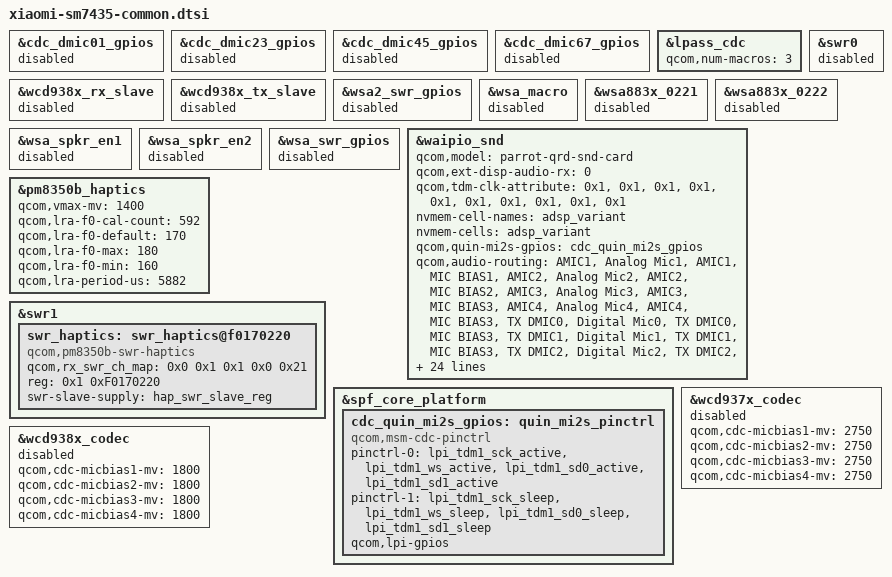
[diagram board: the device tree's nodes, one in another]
#include "parrot-audio-overlay.dtsi"

&cdc_dmic01_gpios {
	status = "disabled";
};

&cdc_dmic23_gpios {
	status = "disabled";
};

&cdc_dmic45_gpios {
	status = "disabled";
};

&cdc_dmic67_gpios {
	status = "disabled";
};

&lpass_cdc {
	qcom,num-macros = <3>;
};

&wcd938x_rx_slave {
	status = "disabled";
};

&wcd938x_tx_slave {
	status = "disabled";
};

&wsa2_swr_gpios {
	status = "disabled";
};

&wsa_macro {
	status = "disabled";
};

&swr0 {
	status = "disabled";
};

&wsa883x_0221 {
	status = "disabled";
};

&wsa883x_0222 {
	status = "disabled";
};

&wsa_spkr_en1 {
	status = "disabled";
};

&wsa_spkr_en2 {
	status = "disabled";
};

&wsa_swr_gpios {
	status = "disabled";
};

&waipio_snd {
    qcom,model = "parrot-qrd-snd-card";
	qcom,ext-disp-audio-rx = <0>;
	qcom,tdm-clk-attribute = <0x1>, <0x1>, <0x1>, <0x1>, <0x1>, <0x1>, <0x1>, <0x1>, <0x1>, <0x1>;
	nvmem-cell-names = "adsp_variant";
	nvmem-cells = <&adsp_variant>;
	qcom,quin-mi2s-gpios = <&cdc_quin_mi2s_gpios>;
	qcom,audio-routing =
		"AMIC1", "Analog Mic1",
		"AMIC1", "MIC BIAS1",
		"AMIC2", "Analog Mic2",
		"AMIC2", "MIC BIAS2",
		"AMIC3", "Analog Mic3",
		"AMIC3", "MIC BIAS3",
		"AMIC4", "Analog Mic4",
		"AMIC4", "MIC BIAS3",
		"TX DMIC0", "Digital Mic0",
		"TX DMIC0", "MIC BIAS3",
		"TX DMIC1", "Digital Mic1",
		"TX DMIC1", "MIC BIAS3",
		"TX DMIC2", "Digital Mic2",
		"TX DMIC2", "MIC BIAS1",
		"TX DMIC3", "Digital Mic3",
		"TX DMIC3", "MIC BIAS1",
		"IN1_HPHL", "HPHL_OUT",
		"IN2_HPHR", "HPHR_OUT",
		"IN3_AUX", "AUX_OUT",
		"HAP_IN", "PCM_OUT",
		"RX_TX DEC0_INP","TX DEC0 MUX",
		"RX_TX DEC1_INP", "TX DEC1 MUX",
		"RX_TX DEC2_INP", "TX DEC2 MUX",
		"RX_TX DEC3_INP", "TX DEC3 MUX",
		"TX SWR_INPUT", "WCD_TX_OUTPUT",
		"VA SWR_INPUT", "VA_SWR_CLK",
		"VA SWR_INPUT", "WCD_TX_OUTPUT",
		"VA_AIF1 CAP", "VA_SWR_CLK",
		"VA_AIF2 CAP", "VA_SWR_CLK",
		"VA_AIF3 CAP", "VA_SWR_CLK",
		"VA DMIC0", "Digital Mic0",
		"VA DMIC1", "Digital Mic1",
		"VA DMIC2", "Digital Mic2",
		"VA DMIC3", "Digital Mic3",
		"VA DMIC0", "VA MIC BIAS3",
		"VA DMIC1", "VA MIC BIAS3",
		"VA DMIC2", "VA MIC BIAS1",
		"VA DMIC3", "VA MIC BIAS1";
	asoc-codec  = <&stub_codec>, <&lpass_cdc>,
		<&wcd937x_codec>, <&swr_haptics>,
		<&wsa883x_0221>, <&wsa883x_0222>;
	asoc-codec-names = "msm-stub-codec.1", "lpass-cdc",
		"wcd937x_codec", "swr-haptics",
		"wsa-codec1", "wsa-codec2";
	qcom,wsa-max-devs = <0>;
	qcom,sku-model = "parrot-qrd-sku1-snd-card";
	qcom,tdm-audio-intf = <0x1>;
};

&pm8350b_haptics {
	qcom,vmax-mv = <1400>;
	qcom,lra-f0-cal-count = <592>;
	qcom,lra-f0-default = <170>;
	qcom,lra-f0-max = <180>;
	qcom,lra-f0-min = <160>;
	qcom,lra-period-us = <5882>;
};

&swr1 {
    swr_haptics: swr_haptics@f0170220 {
        compatible = "qcom,pm8350b-swr-haptics";
        qcom,rx_swr_ch_map = <0x0 0x1 0x1 0x0 0x21>;
        reg = <0x1 0xF0170220>;
        swr-slave-supply = <&hap_swr_slave_reg>;
    };
};

&spf_core_platform {
    cdc_quin_mi2s_gpios: quin_mi2s_pinctrl {
        #gpio-cells = <0x0>;
        compatible = "qcom,msm-cdc-pinctrl";
        pinctrl-names = "aud_active","aud_sleep";
        pinctrl-0 = <&lpi_tdm1_sck_active &lpi_tdm1_ws_active
				&lpi_tdm1_sd0_active &lpi_tdm1_sd1_active>;
        pinctrl-1 = <&lpi_tdm1_sck_sleep &lpi_tdm1_ws_sleep
				&lpi_tdm1_sd0_sleep &lpi_tdm1_sd1_sleep>;
        qcom,lpi-gpios;
        status = "ok";
    };
};

&wcd937x_codec {
	qcom,cdc-micbias1-mv = <2750>;
	qcom,cdc-micbias2-mv = <2750>;
	qcom,cdc-micbias3-mv = <2750>;
	qcom,cdc-micbias4-mv = <2750>;
	status = "disabled";
};

&wcd938x_codec {
	qcom,cdc-micbias1-mv = <1800>;
	qcom,cdc-micbias2-mv = <1800>;
	qcom,cdc-micbias3-mv = <1800>;
	qcom,cdc-micbias4-mv = <1800>;
	status = "disabled";
};
